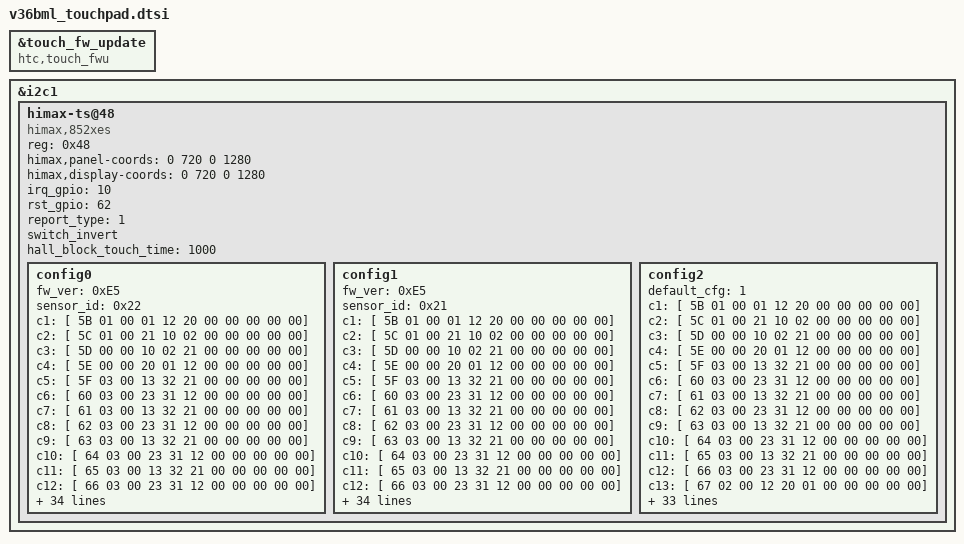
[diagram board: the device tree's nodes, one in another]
	&touch_fw_update {
		compatible = "htc,touch_fwu";
	};
        &i2c1 {
		himax-ts@48 {
			compatible               	= "himax,852xes";
			reg                      	= <0x48>;
				himax,panel-coords	= <0 720 0 1280>;
				himax,display-coords	= <0 720 0 1280>;
				irq_gpio = <10>;
				rst_gpio = <62>;
				report_type	= <1>;
				switch_invert;
				hall_block_touch_time	= <1000>;	/* msec */

			config0 {	//truly
				fw_ver     	= <0xE5>;
				sensor_id     	= <0x22>;
				c1 = [ 5B 01 00 01 12 20 00 00 00 00 00];
				c2 = [ 5C 01 00 21 10 02 00 00 00 00 00];
				c3 = [ 5D 00 00 10 02 21 00 00 00 00 00];
				c4 = [ 5E 00 00 20 01 12 00 00 00 00 00];
				c5 = [ 5F 03 00 13 32 21 00 00 00 00 00];
				c6 = [ 60 03 00 23 31 12 00 00 00 00 00];
				c7 = [ 61 03 00 13 32 21 00 00 00 00 00];
				c8 = [ 62 03 00 23 31 12 00 00 00 00 00];
				c9 = [ 63 03 00 13 32 21 00 00 00 00 00];
				c10 = [ 64 03 00 23 31 12 00 00 00 00 00];
				c11 = [ 65 03 00 13 32 21 00 00 00 00 00];
				c12 = [ 66 03 00 23 31 12 00 00 00 00 00];
				c13 = [ 67 02 00 12 20 01 00 00 00 00 00];
				c14 = [ 68 02 00 02 21 10 00 00 00 00 00];
				c15 = [ 69 02 00 12 20 01 00 00 00 00 00];
				c16 = [ 6A 02 00 02 20 00 00 00 00 00 00];
				c17 = [ 6B 02 00 02 20 00 00 00 00 00 00];
				c18 = [ D5 69 0A 00 00 00 00 00 00 00 00 00 00 00 00 00 00];
				c19 = [ E1 05 01 01 01 02 03 0F 05 0F 06 0F 03 0F 08];
				c20 = [ BC 0A 00 08 00];
				c21 = [ C5 05 1E 00 10 19 1A 0B 1E 02 1F];
				c22 = [ C6 16 10 1E];
				c23 = [ BD 00 0B];
				c24 = [ B9 01 15];
				c25 = [ EC 10 9E 8D];
				c26 = [ B0 00];
				c27 = [ DD 04];
				c28 = [ 42 02];
				c29 = [ CE 00];
				c30 = [ CA A5];
				c31 = [ 3F 00];
				c32 = [ EB 03];
				c33 = [ BA 00];
				c34 = [ BB 00];
				c35 = [ D3 06 01];
				c36 = [ 37 0A 08 FF 08];
				c37 = [ A4 94 62 94 86];
				c38 = [ ED 00 04 0A 0A 04 00 00 00];
				c39 = [ CB 00 0F 0F FF FF 01 00 0F 00 32 00 FF 00];
				c40 = [ 40 01 5A
						5F 13 70 10 D4 00
						64 0F 0D 10 0A 08 08 0F 0F 0C
						2A 22 50 50 20 16 00 00 00 00 00 00
						94 0C F0 83 84 00
						42 2A 0D 10 83 3C 12 05
						11 00 41 42
						0F 14 00 10 00 00
						10 01 3C 64 06 01
						30 2F 3F 08 1C 00 00 00
						04 06 24 05 08 00 00 00
						10 40 0A 54 10 9E 8D 20 00 02 03 10 00 00 64 30
						98 68 64 28 12 A6 30 40
						10 17 20 32 01 06 0B 00
						A5 78 32 08
						0F 19 A0 16
						00 00 04 38 07 80
						03 0E 08 05 55 49 08 00 83 02 4F 53 BD 0A
						04 0D 0A A2 59 7A 00 00 C2 03 6B 56 CC 00
						10 20 20 0F 00 00 00 00];
				c41 = [ 40 0E 0D 27 26 25 24 23 22 21 20 1F 1E 1D 1C 1B FF FF 1A 19 18 17 16 15 14 13 12 11 10 0F 00 01 02 03 04 FF FF FF FF 05 06 07 08 09 0A 0B 0C FF FF FF FF FF FF FF FF
						1F 11 10 11 10 00
						00 00 00 00 00 00
						00 00 00 00 00 00
						1A 7D 12 32 82 C2 05 00
						11 C4 55 C5 48 5C 03 00 00 00
						00 00 00 0A 19 12];
			};

			config1 {	// jtouch
				fw_ver     	= <0xE5>;
				sensor_id     	= <0x21>;
				c1 = [ 5B 01 00 01 12 20 00 00 00 00 00];
				c2 = [ 5C 01 00 21 10 02 00 00 00 00 00];
				c3 = [ 5D 00 00 10 02 21 00 00 00 00 00];
				c4 = [ 5E 00 00 20 01 12 00 00 00 00 00];
				c5 = [ 5F 03 00 13 32 21 00 00 00 00 00];
				c6 = [ 60 03 00 23 31 12 00 00 00 00 00];
				c7 = [ 61 03 00 13 32 21 00 00 00 00 00];
				c8 = [ 62 03 00 23 31 12 00 00 00 00 00];
				c9 = [ 63 03 00 13 32 21 00 00 00 00 00];
				c10 = [ 64 03 00 23 31 12 00 00 00 00 00];
				c11 = [ 65 03 00 13 32 21 00 00 00 00 00];
				c12 = [ 66 03 00 23 31 12 00 00 00 00 00];
				c13 = [ 67 02 00 12 20 01 00 00 00 00 00];
				c14 = [ 68 02 00 02 21 10 00 00 00 00 00];
				c15 = [ 69 02 00 12 20 01 00 00 00 00 00];
				c16 = [ 6A 02 00 02 20 00 00 00 00 00 00];
				c17 = [ 6B 02 00 02 20 00 00 00 00 00 00];
				c18 = [ D5 69 0A 00 00 00 00 00 00 00 00 00 00 00 00 00 00];
				c19 = [ E1 08 01 01 01 02 03 07 03 0F 03 0F 03 0F 08];
				c20 = [ BC 00 00 00 00];
				c21 = [ C5 05 1D 00 10 1C 1A 0B 1E 02 1F];
				c22 = [ C6 16 10 1E];
				c23 = [ BD 00 0B];
				c24 = [ B9 01 15];
				c25 = [ EC 10 9E 8D];
				c26 = [ B0 00];
				c27 = [ DD 04];
				c28 = [ 42 02];
				c29 = [ CE 00];
				c30 = [ CA A5];
				c31 = [ 3F 00];
				c32 = [ EB 03];
				c33 = [ BA 00];
				c34 = [ BB 00];
				c35 = [ D3 06 01];
				c36 = [ 37 22 08 FF 08];
				c37 = [ A4 94 62 94 86];
				c38 = [ ED 00 04 0A 0A 04 00 00 00];
				c39 = [ CB 00 0F 0F FF FF 01 00 0F 00 32 00 FF 00];
				c40 = [ 40 01 5A
						5F 13 70 13 04 00
						64 0F 0D 10 12 0A 08 0F 0F 0C
						2A 22 50 50 20 16 00 00 00 00 00 00
						94 0C F0 83 84 00
						42 2A 0D 10 83 3C 12 05
						11 00 41 42
						0F 14 00 10 00 00
						10 01 3C 64 06 06
						30 2F 3F 08 1C 00 00 00
						04 06 24 08 08 00 00 00
						10 40 0A 54 10 9E 8D 20 00 02 03 10 00 00 64 30
						98 68 64 28 12 A6 30 40
						10 17 20 32 01 06 0B 00
						A5 78 32 08
						0F 19 A0 16
						00 00 04 38 07 80
						03 0E 08 05 55 49 08 00 83 02 4F 53 BD 0A
						04 0D 0A A2 59 7A 00 00 C2 03 6B 56 CC 00
						10 20 20 0F 00 00 00 00];
				c41 = [ 40 0E 0D 27 26 25 24 23 22 21 20 1F 1E 1D 1C 1B FF FF 1A 19 18 17 16 15 14 13 12 11 10 0F 00 01 02 03 04 FF FF FF FF 05 06 07 08 09 0A 0B 0C FF FF FF FF FF FF FF FF
						1F 11 10 11 10 00
						00 00 00 00 00 00
						00 00 00 00 00 00
						1A 7D 12 32 82 C2 05 00
						11 C4 55 C5 48 5C 03 00 00 00
						00 00 00 0A 19 12];
			};

			config2 {	//default using truly
				default_cfg	= <1>;
				c1 = [ 5B 01 00 01 12 20 00 00 00 00 00];
				c2 = [ 5C 01 00 21 10 02 00 00 00 00 00];
				c3 = [ 5D 00 00 10 02 21 00 00 00 00 00];
				c4 = [ 5E 00 00 20 01 12 00 00 00 00 00];
				c5 = [ 5F 03 00 13 32 21 00 00 00 00 00];
				c6 = [ 60 03 00 23 31 12 00 00 00 00 00];
				c7 = [ 61 03 00 13 32 21 00 00 00 00 00];
				c8 = [ 62 03 00 23 31 12 00 00 00 00 00];
				c9 = [ 63 03 00 13 32 21 00 00 00 00 00];
				c10 = [ 64 03 00 23 31 12 00 00 00 00 00];
				c11 = [ 65 03 00 13 32 21 00 00 00 00 00];
				c12 = [ 66 03 00 23 31 12 00 00 00 00 00];
				c13 = [ 67 02 00 12 20 01 00 00 00 00 00];
				c14 = [ 68 02 00 02 21 10 00 00 00 00 00];
				c15 = [ 69 02 00 12 20 01 00 00 00 00 00];
				c16 = [ 6A 02 00 02 20 00 00 00 00 00 00];
				c17 = [ 6B 02 00 02 20 00 00 00 00 00 00];
				c18 = [ D5 69 0A 00 00 00 00 00 00 00 00 00 00 00 00 00 00];
				c19 = [ E1 05 01 01 01 02 03 0F 05 0F 06 0F 03 0F 08];
				c20 = [ BC 0A 00 08 00];
				c21 = [ C5 05 1E 00 10 19 1A 0B 1E 02 1F];
				c22 = [ C6 16 10 1E];
				c23 = [ BD 00 0B];
				c24 = [ B9 01 15];
				c25 = [ EC 10 9E 8D];
				c26 = [ B0 00];
				c27 = [ DD 04];
				c28 = [ 42 02];
				c29 = [ CE 00];
				c30 = [ CA A5];
				c31 = [ 3F 00];
				c32 = [ EB 03];
				c33 = [ BA 00];
				c34 = [ BB 00];
				c35 = [ D3 06 01];
				c36 = [ 37 0A 08 FF 08];
				c37 = [ A4 94 62 94 86];
				c38 = [ ED 00 04 0A 0A 04 00 00 00];
				c39 = [ CB 00 0F 0F FF FF 01 00 0F 00 32 00 FF 00];
				c40 = [ 40 01 5A
						5F 13 70 10 D4 00
						64 0F 0D 10 0A 08 08 0F 0F 0C
						2A 22 50 50 20 16 00 00 00 00 00 00
						94 0C F0 83 84 00
						42 2A 0D 10 83 3C 12 05
						11 00 41 42
						0F 14 00 10 00 00
						10 01 3C 64 06 01
						30 2F 3F 08 1C 00 00 00
						04 06 24 05 08 00 00 00
						10 40 0A 54 10 9E 8D 20 00 02 03 10 00 00 64 30
						98 68 64 28 12 A6 30 40
						10 17 20 32 01 06 0B 00
						A5 78 32 08
						0F 19 A0 16
						00 00 04 38 07 80
						03 0E 08 05 55 49 08 00 83 02 4F 53 BD 0A
						04 0D 0A A2 59 7A 00 00 C2 03 6B 56 CC 00
						10 20 20 0F 00 00 00 00];
				c41 = [ 40 0E 0D 27 26 25 24 23 22 21 20 1F 1E 1D 1C 1B FF FF 1A 19 18 17 16 15 14 13 12 11 10 0F 00 01 02 03 04 FF FF FF FF 05 06 07 08 09 0A 0B 0C FF FF FF FF FF FF FF FF
						1F 11 10 11 10 00
						00 00 00 00 00 00
						00 00 00 00 00 00
						1A 7D 12 32 82 C2 05 00
						11 C4 55 C5 48 5C 03 00 00 00
						00 00 00 0A 19 12];
			};
		};
	};
